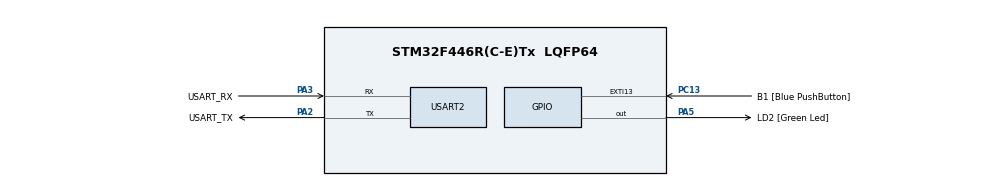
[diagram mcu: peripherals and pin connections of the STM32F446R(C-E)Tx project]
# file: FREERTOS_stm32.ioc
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FREERTOS.Tasks01=defaultTask,24,128,StartDefaultTask,Default,NULL,Dynamic,NULL,NULL
FREERTOS.configENABLE_FPU=1
Mcu.Family=STM32F4
Mcu.Name=STM32F446R(C-E)Tx
Mcu.Package=LQFP64
NVIC.PriorityGroup=NVIC_PRIORITYGROUP_4
NVIC.USART2_IRQn=true\:5\:0\:false\:false\:true\:true\:true\:true\:true
PA13.GPIO_Label=TMS
PA13.Mode=Serial_Wire
PA13.Signal=SYS_JTMS-SWDIO
PA14.GPIO_Label=TCK
PA14.Mode=Serial_Wire
PA14.Signal=SYS_JTCK-SWCLK
PA2.GPIO_Label=USART_TX
PA2.Mode=Asynchronous
PA2.Signal=USART2_TX
PA3.GPIO_Label=USART_RX
PA3.Mode=Asynchronous
PA3.Signal=USART2_RX
PA5.GPIO_Label=LD2 [Green Led]
PA5.Signal=GPIO_Output
PB3.GPIO_Label=SWO
PB3.Signal=SYS_JTDO-SWO
PC13.GPIO_Label=B1 [Blue PushButton]
PC13.GPIO_ModeDefaultEXTI=GPIO_MODE_IT_FALLING
PC13.Signal=GPXTI13
PC14-OSC32_IN.Mode=LSE-External-Oscillator
PC14-OSC32_IN.Signal=RCC_OSC32_IN
PC15-OSC32_OUT.Mode=LSE-External-Oscillator
PC15-OSC32_OUT.Signal=RCC_OSC32_OUT
PH0-OSC_IN.Mode=HSE-External-Oscillator
PH0-OSC_IN.Signal=RCC_OSC_IN
PH1-OSC_OUT.Mode=HSE-External-Oscillator
PH1-OSC_OUT.Signal=RCC_OSC_OUT
ProjectManager.HeapSize=0x200
ProjectManager.StackSize=0x400
ProjectManager.TargetToolchain=CMake
RCC.48MHZClocksFreq_Value=84000000
RCC.AHBFreq_Value=84000000
RCC.APB1CLKDivider=RCC_HCLK_DIV2
RCC.APB1Freq_Value=42000000
RCC.APB1TimFreq_Value=84000000
RCC.APB2Freq_Value=84000000
RCC.APB2TimFreq_Value=84000000
RCC.CortexFreq_Value=84000000
RCC.FLatency-AdvancedSettings=FLASH_LATENCY_2
RCC.HCLKFreq_Value=84000000
RCC.HSE_VALUE=8000000
RCC.HSI_VALUE=16000000
RCC.PLLN=336
RCC.PLLP=RCC_PLLP_DIV4
RCC.SYSCLKFreq_VALUE=84000000
RCC.SYSCLKSource=RCC_SYSCLKSOURCE_PLLCLK
RCC.USBFreq_Value=168000000
RCC.VCOOutputFreq_Value=336000000
USART2.VirtualMode=VM_ASYNC
VP_FREERTOS_VS_CMSIS_V2.Mode=CMSIS_V2
board=NUCLEO-F446RE

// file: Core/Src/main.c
/* USER CODE BEGIN Header */
/**
  ******************************************************************************
  * @file           : main.c
  * @brief          : Main program body
  ******************************************************************************
  * @attention
  *
  * Copyright (c) 2025 STMicroelectronics.
  * All rights reserved.
  *
  * This software is licensed under terms that can be found in the LICENSE file
  * in the root directory of this software component.
  * If no LICENSE file comes with this software, it is provided AS-IS.
  *
  ******************************************************************************
  */
/* USER CODE END Header */
#include "main.h"
#include "cmsis_os.h"
#include "init.h"
#include "uart.h"

/* Definitions for defaultTask */
osThreadId_t defaultTaskHandle;
const osThreadAttr_t defaultTask_attributes = {
  .name = "defaultTask",
  .stack_size = 128 * 4,
  .priority = (osPriority_t) osPriorityNormal,
};

void StartDefaultTask(void *argument);

extern UART_HandleTypeDef huart2;

int main(void)
{
  /* MCU Configuration--------------------------------------------------------*/

  /* Reset of all peripherals, Initializes the Flash interface and the Systick. */
  HAL_Init();

  /* Configure the system clock */
  SystemClock_Config();

  /* Initialize all configured peripherals */
  MX_GPIO_Init();
  MX_USART2_UART_Init();

  /* Init scheduler */
  osKernelInitialize();

  defaultTaskHandle = osThreadNew(StartDefaultTask, NULL, &defaultTask_attributes);

  /* Start scheduler */
  osKernelStart();

  /* We should never get here as control is now taken by the scheduler */

  /* Infinite loop */
  while (1)
  {

  }
}

void StartDefaultTask(void *argument)
{
  /* USER CODE BEGIN 5 */
  /* Infinite loop */
  while(1)
  {
      char hello[6] = "hello\n";
      HAL_UART_Transmit(&huart2, (const char *) hello, 6, 100);
      vTaskDelay(1000);
  }
  /* USER CODE END 5 */
}

void HAL_TIM_PeriodElapsedCallback(TIM_HandleTypeDef *htim)
{
  if (htim->Instance == TIM7)
  {
    HAL_IncTick();
  }
}

void Error_Handler(void)
{
  __disable_irq();
  while (1)
  {
  }
}
